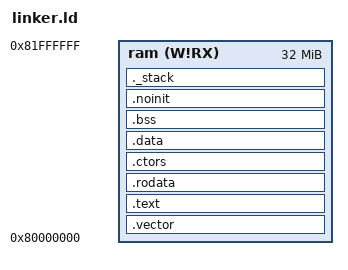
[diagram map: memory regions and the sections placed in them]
/*======================================================================*/
/* Proxy kernel linker script                                           */
/*======================================================================*/
/* This is the linker script used when building the proxy kernel. */

/*----------------------------------------------------------------------*/
/* Setup                                                                */
/*----------------------------------------------------------------------*/

/* The OUTPUT_ARCH command specifies the machine architecture where the
   argument is one of the names used in the BFD library. More
   specifically one of the entires in bfd/cpu-mips.c */

/*
This is free and unencumbered software released into the public domain.

Anyone is free to copy, modify, publish, use, compile, sell, or
distribute this software, either in source code form or as a compiled
binary, for any purpose, commercial or non-commercial, and by any
means.
*/
OUTPUT_FORMAT("elf32-littleriscv", "elf32-littleriscv", "elf32-littleriscv")
OUTPUT_ARCH(riscv)
ENTRY(crtStart)

MEMORY {
  ram (W!RX) : ORIGIN = 0x80000000, LENGTH = 32M
}

_stack_size = 4k;

SECTIONS
{
  .vector : {
    *crt.o(.text);
  } > ram
  
  .text : {
    *(.text);
    *(.text.*);
    end = .;
  } > ram
  
  .rodata : {
    *(.rdata)
    *(.rodata .rodata.*)
    *(.gnu.linkonce.r.*)
  } > ram
  
  .ctors : {
    . = ALIGN(4);
    _ctors_start = .;
    KEEP(*(.init_array*))
    KEEP (*(SORT(.ctors.*)))
    KEEP (*(.ctors))
    . = ALIGN(4);
    _ctors_end = .;
  } > ram
  
  .data : {
    *(.rdata)
    *(.rodata .rodata.*)
    *(.gnu.linkonce.r.*)
    *(.data .data.*)
    *(.gnu.linkonce.d.*)
    . = ALIGN(8);
    PROVIDE( __global_pointer$ = . + 0x800 );
    *(.sdata .sdata.*)
    *(.gnu.linkonce.s.*)
    . = ALIGN(8);
    *(.srodata.cst16)
    *(.srodata.cst8)
    *(.srodata.cst4)
    *(.srodata.cst2)
    *(.srodata .srodata.*)
  } > ram
  
  .bss (NOLOAD) : {
    . = ALIGN(4);
    _bss_start = .;
    *(.sbss*)
    *(.gnu.linkonce.sb.*)
    *(.bss .bss.*)
    *(.gnu.linkonce.b.*)
    *(COMMON)
    . = ALIGN(4);
    _bss_end = .;
  } > ram
  
  .noinit (NOLOAD) : {
    . = ALIGN(4);
    *(.noinit .noinit.*)
    . = ALIGN(4);
  } > ram
  
  ._stack (NOLOAD) : {
    . = ALIGN(16);
    PROVIDE (_stack_end = .);
    . = . + _stack_size;
    . = ALIGN(16);
    PROVIDE (_stack_start = .);
  } > ram
}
